# BlueNRG2 register map
Vendor: STMicroelectronics; Series: BlueNRG2; File version: 1.2.1
CPU: CM0 r0p0, little endian, no MPU, no FPU, 2 interrupt priority bits
Registers are 32-bit, read-write, reset 0x0 unless marked. A register's access mark holds for its fields unless they carry their own. Offsets are from the block's base; [hi:lo] are bit positions; {n}, {i} and the like mark numbered series; 'fields as' and 'values as' point back to an identical list.

## GPIO — GPIO Controller
Base 0x40000000
0x00 DATA (reset mask 0x3FFFFFF) — IO0 to IO14 data value.<p>Writing to a bit will drive the written value on the corresponding IO when it is configured in GPIO mode and the output direction. Reading a bit indicates the pin value</p>
0x04 OEN (reset mask 0x3FFFFFF) — GPIO output enable register (1 bit per GPIO).<ul><li>0: input mode.</li><li>1: output mode</li></ul>
0x08 PE reset 0x3FFFFFF (reset mask 0x3FFFFFF) — Pull enable (1 bit per IO).<ul><li>0: pull disabled.</li><li>1: pull enabled</li></ul>
0x0C DS (reset mask 0x3FFFFFF) — IO driver strength (1 bit per IO).<ul><li>0: 2mA.</li><li>1: 4 mA</li></ul>
0x10 IS (reset mask 0x3FFFFFF) — Interrupt sense register (1 bit per IO).<ul><li>0: edge detection.</li><li>1: level detection</li></ul>
0x14 IBE (reset mask 0x3FFFFFF) — Interrupt edge register (1 bit per IO).<ul><li>0: single edge.</li><li>1: both edges</li></ul>
0x18 IEV (reset mask 0x3FFFFFF) — Interrupt event register (1 bit per IO).<ul><li>0: falling edge or low level.</li><li>1: rising edge or high level</li></ul>
0x1C IE (reset mask 0x3FFFFFF) — Interrupt mask register (1 bit per IO).<ul><li>0: interrupt disabled.</li><li>1: interrupt enabled.</li></ul>
0x20 RIS ro (reset mask 0x3FFFFFF) — Raw interrupt status register (1 bit per IO)
0x24 MIS ro (reset mask 0x3FFFFFF) — Masked interrupt status register (1 bit per IO)
0x28 IC wo (reset mask 0x3FFFFFF) write-1-clears — Interrupt clear register (1 bit per IO).<ul><li>0: no effect.</li><li>1: clear interrupt</li></ul>
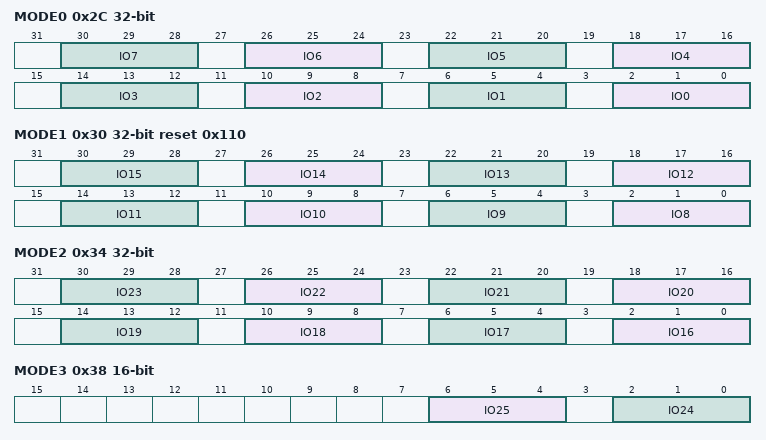
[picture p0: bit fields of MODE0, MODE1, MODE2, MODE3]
0x2C MODE0 — Select mode for IO0 to IO7.<ul><li>000b: GPIO mode.</li><li>001b: Serial1 mode.</li><li>100b: Serial0 mode.</li><li>101b: Microphone/ADC mode.</li></ul>
  [all] fields
    0=GPIO_MODE; 1=SERIAL1_MODE; 2=STANDALONE_MODE; 3=BLUE_MODE (BLE mode); 4=SERIAL0_MODE; 5=MICROPHONE_ADC_MODE (ADC mode for microphone)
  [4n+2:4n] IO{n} (n=0..7) — IO{n} mode
0x30 MODE1 reset 0x110 — Select mode for IO8 to IO15.<ul><li>000b: GPIO mode.</li><li>001b: Serial1 mode.</li><li>100b: Serial0 mode.</li><li>101b: Microphone/ADC mode.</li></ul>
  [all] fields
    values as the fields of MODE0
  [4n-30:4n-32] IO{n} (n=8..15) — IO{n} mode
0x34 MODE2 — Select mode for IO16 to IO23
  [all] fields
    values as the fields of MODE0
  [4n-62:4n-64] IO{n} (n=16..23) — IO{n} mode
0x38 MODE3 16-bit — Select mode for IO24 to IO25
  [6:4] IO25 — IO25 mode
    values as the fields of MODE0
  [2:0] IO24 — IO24 mode
    values as the fields of MODE0
0x3C DATS (reset mask 0x3FFFFFF) — Set some bits of DATA when in GPIO mode without affecting the others (1 bit per IO).<ul><li>0: no effect.</li><li>1: set at 1 the bit</li></ul>
0x40 DATC (reset mask 0x3FFFFFF) — Clear some bits of DATA when in GPIO mode without affecting the others (1 bit per IO).<ul><li>0: no effect.</li><li>1: clear at 0 the bit</li></ul>
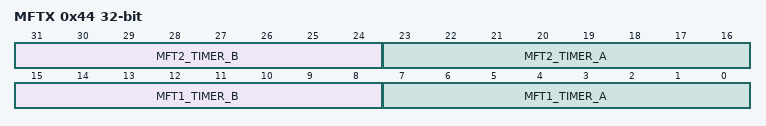
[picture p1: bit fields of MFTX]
0x44 MFTX — Select the IO to be used as capture input for the MFTX timers
  [all] fields
    {v}=IO{v} (v=0..25)
  [31:24] MFT2_TIMER_B — Selects which IO must be used as input pin TnB for the MFT2 peripheral. Only mode 2 and mode 4.<ul><li>0x00: IO0.</li><li>0x01: IO1</li><li>0x02: IO2</li><li>...</li><li>0x0E: IO14</li></ul>
  [23:16] MFT2_TIMER_A — Selects which IO must be used as input pin TnA for the MFT2 peripheral. Only mode 2 and mode 4.<ul><li>0x00: IO0.</li><li>0x01: IO1</li><li>0x02: IO2</li><li>...</li><li>0x0E: IO14</li></ul>
  [15:8] MFT1_TIMER_B — Selects which IO must be used as input pin TnB for the MFT1 peripheral. Only mode 2 and mode 4.<ul><li>0x00: IO0.</li><li>0x01: IO1</li><li>0x02: IO2</li><li>...</li><li>0x0E: IO14</li></ul>
  [7:0] MFT1_TIMER_A — Selects which IO must be used as input pin TnA for the MFT1 peripheral. Only mode 2 and mode 4.<ul><li>0x00: IO0.</li><li>0x01: IO1</li><li>0x02: IO2</li><li>...</li><li>0x0E: IO14</li></ul>
